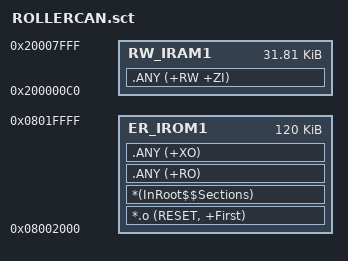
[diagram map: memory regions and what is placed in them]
; *************************************************************
; *** Scatter-Loading Description File generated by uVision ***
; *************************************************************

LR_IROM1 0x08002000 0x0001E000  {    ; load region size_region
  ER_IROM1 0x08002000 0x0001E000  {  ; load address = execution address
   *.o (RESET, +First)
   *(InRoot$$Sections)
   .ANY (+RO)
   .ANY (+XO)
  }
  RW_IRAM1 0x200000C0 0x00007F40  {  ; RW data
   .ANY (+RW +ZI)
  }
}

